AUTOSAR XML (schema 4-0-3)
standard types defined: Boolean, UInt16, UInt32, UInt8
package /AUTOSAR_Platform/DataConstrs
  range DC_Boolean: raw 0..1
  range DC_UInt16: raw 0..65535
  range DC_UInt8: raw 0..255
package /PATAC/MSM/ComponentTypes
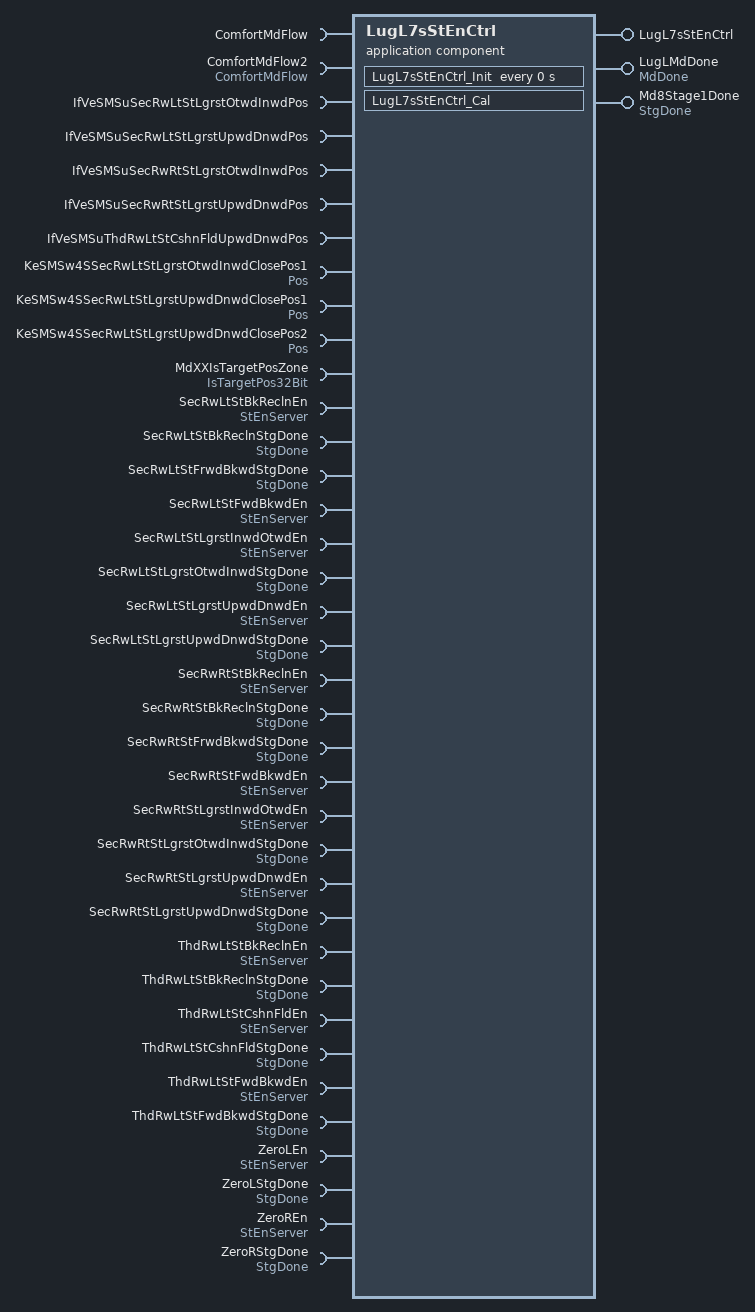
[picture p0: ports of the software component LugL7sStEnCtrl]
  application sw component type LugL7sStEnCtrl
    provide port LugL7sStEnCtrl: server-com-spec{operation=LugL7sStEnCtrl/Cal, queue-length=1}, provided-interface=LugL7sStEnCtrl
    provide port LugLMdDone: nonqueued-sender-com-spec{data-element=MdDone/Val, init-value=0}, provided-interface=MdDone
    provide port Md8Stage1Done: nonqueued-sender-com-spec{data-element=StgDone/Val, init-value=0}, provided-interface=StgDone
    37 x require port:
      ComfortMdFlow: client-com-spec=ComfortMdFlow/Cal, required-interface=ComfortMdFlow
      ComfortMdFlow2: client-com-spec=ComfortMdFlow/Cal, required-interface=ComfortMdFlow
      IfVeSMSuSecRwLtStLgrstOtwdInwdPos: nonqueued-receiver-com-spec{data-element=IfVeSMSuSecRwLtStLgrstOtwdInwdPos/Val, filter=data-filter-type=ALWAYS, init-value=0}, required-interface=IfVeSMSuSecRwLtStLgrstOtwdInwdPos
      IfVeSMSuSecRwLtStLgrstUpwdDnwdPos: nonqueued-receiver-com-spec{data-element=IfVeSMSuSecRwLtStLgrstUpwdDnwdPos/Val, filter=data-filter-type=ALWAYS, init-value=0}, required-interface=IfVeSMSuSecRwLtStLgrstUpwdDnwdPos
      IfVeSMSuSecRwRtStLgrstOtwdInwdPos: nonqueued-receiver-com-spec{data-element=IfVeSMSuSecRwRtStLgrstOtwdInwdPos/Val, filter=data-filter-type=ALWAYS, init-value=0}, required-interface=IfVeSMSuSecRwRtStLgrstOtwdInwdPos
      IfVeSMSuSecRwRtStLgrstUpwdDnwdPos: nonqueued-receiver-com-spec{data-element=IfVeSMSuSecRwRtStLgrstUpwdDnwdPos/Val, filter=data-filter-type=ALWAYS, init-value=0}, required-interface=IfVeSMSuSecRwRtStLgrstUpwdDnwdPos
      IfVeSMSuThdRwLtStCshnFldUpwdDnwdPos: nonqueued-receiver-com-spec{data-element=IfVeSMSuThdRwLtStCshnFldUpwdDnwdPos/Val, filter=data-filter-type=ALWAYS, init-value=0}, required-interface=IfVeSMSuThdRwLtStCshnFldUpwdDnwdPos
      KeSMSw4SSecRwLtStLgrstOtwdInwdClosePos1: parameter-require-com-spec{init-value=0, parameter=Val}, required-interface=Pos
      KeSMSw4SSecRwLtStLgrstUpwdDnwdClosePos1: parameter-require-com-spec{init-value=0, parameter=Val}, required-interface=Pos
      KeSMSw4SSecRwLtStLgrstUpwdDnwdClosePos2: parameter-require-com-spec{init-value=0, parameter=Val}, required-interface=Pos
      MdXXIsTargetPosZone: nonqueued-receiver-com-spec{data-element=IsTargetPos32Bit/Val, filter=data-filter-type=ALWAYS, init-value=0}, required-interface=IsTargetPos32Bit
      SecRwLtStBkReclnEn: required-com-specs=[Clear, Get, Set], required-interface=StEnServer
      SecRwLtStBkReclnStgDone: nonqueued-receiver-com-spec{data-element=StgDone/Val, filter=data-filter-type=ALWAYS, init-value=0}, required-interface=StgDone
      SecRwLtStFrwdBkwdStgDone: nonqueued-receiver-com-spec{data-element=StgDone/Val, filter=data-filter-type=ALWAYS, init-value=0}, required-interface=StgDone
      SecRwLtStFwdBkwdEn: required-com-specs=[Clear, Get, Set], required-interface=StEnServer
      SecRwLtStLgrstInwdOtwdEn: required-com-specs=[Clear, Get, Set], required-interface=StEnServer
      SecRwLtStLgrstOtwdInwdStgDone: nonqueued-receiver-com-spec{data-element=StgDone/Val, filter=data-filter-type=ALWAYS, init-value=0}, required-interface=StgDone
      SecRwLtStLgrstUpwdDnwdEn: required-com-specs=[Clear, Get, Set], required-interface=StEnServer
      SecRwLtStLgrstUpwdDnwdStgDone: nonqueued-receiver-com-spec{data-element=StgDone/Val, filter=data-filter-type=ALWAYS, init-value=0}, required-interface=StgDone
      SecRwRtStBkReclnEn: required-com-specs=[Clear, Get, Set], required-interface=StEnServer
      SecRwRtStBkReclnStgDone: nonqueued-receiver-com-spec{data-element=StgDone/Val, filter=data-filter-type=ALWAYS, init-value=0}, required-interface=StgDone
      SecRwRtStFrwdBkwdStgDone: nonqueued-receiver-com-spec{data-element=StgDone/Val, filter=data-filter-type=ALWAYS, init-value=0}, required-interface=StgDone
      SecRwRtStFwdBkwdEn: required-com-specs=[Clear, Get, Set], required-interface=StEnServer
      SecRwRtStLgrstInwdOtwdEn: required-com-specs=[Clear, Get, Set], required-interface=StEnServer
      SecRwRtStLgrstOtwdInwdStgDone: nonqueued-receiver-com-spec{data-element=StgDone/Val, filter=data-filter-type=ALWAYS, init-value=0}, required-interface=StgDone
      SecRwRtStLgrstUpwdDnwdEn: required-com-specs=[Clear, Get, Set], required-interface=StEnServer
      SecRwRtStLgrstUpwdDnwdStgDone: nonqueued-receiver-com-spec{data-element=StgDone/Val, filter=data-filter-type=ALWAYS, init-value=0}, required-interface=StgDone
      ThdRwLtStBkReclnEn: required-com-specs=[Clear, Get, Set], required-interface=StEnServer
      ThdRwLtStBkReclnStgDone: nonqueued-receiver-com-spec{data-element=StgDone/Val, filter=data-filter-type=ALWAYS, init-value=0}, required-interface=StgDone
      ThdRwLtStCshnFldEn: required-com-specs=[Clear, Get, Set], required-interface=StEnServer
      ThdRwLtStCshnFldStgDone: nonqueued-receiver-com-spec{data-element=StgDone/Val, filter=data-filter-type=ALWAYS, init-value=0}, required-interface=StgDone
      ThdRwLtStFwdBkwdEn: required-com-specs=[Clear, Get, Set], required-interface=StEnServer
      ThdRwLtStFwdBkwdStgDone: nonqueued-receiver-com-spec{data-element=StgDone/Val, filter=data-filter-type=ALWAYS, init-value=0}, required-interface=StgDone
      ZeroLEn: required-com-specs=[Clear, Get, Set], required-interface=StEnServer
      ZeroLStgDone: nonqueued-receiver-com-spec{data-element=StgDone/Val, filter=data-filter-type=ALWAYS, init-value=0}, required-interface=StgDone
      ZeroREn: required-com-specs=[Clear, Get, Set], required-interface=StEnServer
      ZeroRStgDone: nonqueued-receiver-com-spec{data-element=StgDone/Val, filter=data-filter-type=ALWAYS, init-value=0}, required-interface=StgDone
    behavior LugL7sStEnCtrl_InternalBehavior
      operation invoked event OIT_LugLStEnCtrl_Cal_LugL7sStEnCtrl_Cal: start-on-event=LugL7sStEnCtrl_Cal, operation=LugL7sStEnCtrl.Cal
      timing event LugL7sStEnCtrl_InitEvent: start-on-event=LugL7sStEnCtrl_Init, period=0
      runnable LugL7sStEnCtrl_Cal
        data-receive-point-by-arguments:
          19 x access:
            REC_IfVeSMSuSecRwLtStLgrstOtwdInwdPos_Val: accessed-variable=IfVeSMSuSecRwLtStLgrstOtwdInwdPos.Val
            REC_IfVeSMSuSecRwLtStLgrstUpwdDnwdPos_Val: accessed-variable=IfVeSMSuSecRwLtStLgrstUpwdDnwdPos.Val
            REC_IfVeSMSuSecRwRtStLgrstOtwdInwdPos_Val: accessed-variable=IfVeSMSuSecRwRtStLgrstOtwdInwdPos.Val
            REC_IfVeSMSuSecRwRtStLgrstUpwdDnwdPos_Val: accessed-variable=IfVeSMSuSecRwRtStLgrstUpwdDnwdPos.Val
            REC_IfVeSMSuThdRwLtStCshnFldUpwdDnwdPos_Val: accessed-variable=IfVeSMSuThdRwLtStCshnFldUpwdDnwdPos.Val
            REC_MdXXIsTargetPosZone_Val: accessed-variable=MdXXIsTargetPosZone.Val
            REC_SecRwLtStBkReclnStgDone_Val: accessed-variable=SecRwLtStBkReclnStgDone.Val
            REC_SecRwLtStFrwdBkwdStgDone_Val: accessed-variable=SecRwLtStFrwdBkwdStgDone.Val
            REC_SecRwLtStLgrstOtwdInwdStgDone_Val: accessed-variable=SecRwLtStLgrstOtwdInwdStgDone.Val
            REC_SecRwLtStLgrstUpwdDnwdStgDone_Val: accessed-variable=SecRwLtStLgrstUpwdDnwdStgDone.Val
            REC_SecRwRtStBkReclnStgDone_Val: accessed-variable=SecRwRtStBkReclnStgDone.Val
            REC_SecRwRtStFrwdBkwdStgDone_Val: accessed-variable=SecRwRtStFrwdBkwdStgDone.Val
            REC_SecRwRtStLgrstOtwdInwdStgDone_Val: accessed-variable=SecRwRtStLgrstOtwdInwdStgDone.Val
            REC_SecRwRtStLgrstUpwdDnwdStgDone_Val: accessed-variable=SecRwRtStLgrstUpwdDnwdStgDone.Val
            REC_ThdRwLtStBkReclnStgDone_Val: accessed-variable=ThdRwLtStBkReclnStgDone.Val
            REC_ThdRwLtStCshnFldStgDone_Val: accessed-variable=ThdRwLtStCshnFldStgDone.Val
            REC_ThdRwLtStFwdBkwdStgDone_Val: accessed-variable=ThdRwLtStFwdBkwdStgDone.Val
            REC_ZeroLStgDone_Val: accessed-variable=ZeroLStgDone.Val
            REC_ZeroRStgDone_Val: accessed-variable=ZeroRStgDone.Val
        data-send-points:
          access SEND_LugLMdDone_Val: accessed-variable=LugLMdDone.Val
          access SEND_Md8Stage1Done_Val: accessed-variable=Md8Stage1Done.Val
        parameter access PA_KeSMSw4SSecRwLtStLgrstOtwdInwdClosePos1_Val: accessed-parameter=KeSMSw4SSecRwLtStLgrstOtwdInwdClosePos1.Val
        parameter access PA_KeSMSw4SSecRwLtStLgrstUpwdDnwdClosePos1_Val: accessed-parameter=KeSMSw4SSecRwLtStLgrstUpwdDnwdClosePos1.Val
        parameter access PA_KeSMSw4SSecRwLtStLgrstUpwdDnwdClosePos2_Val: accessed-parameter=KeSMSw4SSecRwLtStLgrstUpwdDnwdClosePos2.Val
        28 x sync call, all with timeout=0:
          SC_ComfortMdFlow_Cal: operation=ComfortMdFlow.Cal
          SC_ComfortMdFlow2_Cal: operation=ComfortMdFlow2.Cal
          SC_SecRwLtStBkReclnEn_Clear: operation=SecRwLtStBkReclnEn.Clear
          SC_SecRwLtStBkReclnEn_Set: operation=SecRwLtStBkReclnEn.Set
          SC_SecRwLtStFwdBkwdEn_Clear: operation=SecRwLtStFwdBkwdEn.Clear
          SC_SecRwLtStFwdBkwdEn_Set: operation=SecRwLtStFwdBkwdEn.Set
          SC_SecRwLtStLgrstInwdOtwdEn_Clear: operation=SecRwLtStLgrstInwdOtwdEn.Clear
          SC_SecRwLtStLgrstInwdOtwdEn_Set: operation=SecRwLtStLgrstInwdOtwdEn.Set
          SC_SecRwLtStLgrstUpwdDnwdEn_Clear: operation=SecRwLtStLgrstUpwdDnwdEn.Clear
          SC_SecRwLtStLgrstUpwdDnwdEn_Set: operation=SecRwLtStLgrstUpwdDnwdEn.Set
          SC_SecRwRtStBkReclnEn_Clear: operation=SecRwRtStBkReclnEn.Clear
          SC_SecRwRtStBkReclnEn_Set: operation=SecRwRtStBkReclnEn.Set
          SC_SecRwRtStFwdBkwdEn_Clear: operation=SecRwRtStFwdBkwdEn.Clear
          SC_SecRwRtStFwdBkwdEn_Set: operation=SecRwRtStFwdBkwdEn.Set
          SC_SecRwRtStLgrstInwdOtwdEn_Clear: operation=SecRwRtStLgrstInwdOtwdEn.Clear
          SC_SecRwRtStLgrstInwdOtwdEn_Set: operation=SecRwRtStLgrstInwdOtwdEn.Set
          SC_SecRwRtStLgrstUpwdDnwdEn_Clear: operation=SecRwRtStLgrstUpwdDnwdEn.Clear
          SC_SecRwRtStLgrstUpwdDnwdEn_Set: operation=SecRwRtStLgrstUpwdDnwdEn.Set
          SC_ThdRwLtStBkReclnEn_Clear: operation=ThdRwLtStBkReclnEn.Clear
          SC_ThdRwLtStBkReclnEn_Set: operation=ThdRwLtStBkReclnEn.Set
          SC_ThdRwLtStCshnFldEn_Clear: operation=ThdRwLtStCshnFldEn.Clear
          SC_ThdRwLtStCshnFldEn_Set: operation=ThdRwLtStCshnFldEn.Set
          SC_ThdRwLtStFwdBkwdEn_Clear: operation=ThdRwLtStFwdBkwdEn.Clear
          SC_ThdRwLtStFwdBkwdEn_Set: operation=ThdRwLtStFwdBkwdEn.Set
          SC_ZeroLEn_Clear: operation=ZeroLEn.Clear
          SC_ZeroLEn_Set: operation=ZeroLEn.Set
          SC_ZeroREn_Clear: operation=ZeroREn.Clear
          SC_ZeroREn_Set: operation=ZeroREn.Set
      runnable LugL7sStEnCtrl_Init
        parameter access PA_KeSMSw4SSecRwLtStLgrstOtwdInwdClosePos1_Val: accessed-parameter=KeSMSw4SSecRwLtStLgrstOtwdInwdClosePos1.Val
        parameter access PA_KeSMSw4SSecRwLtStLgrstUpwdDnwdClosePos1_Val: accessed-parameter=KeSMSw4SSecRwLtStLgrstUpwdDnwdClosePos1.Val
        parameter access PA_KeSMSw4SSecRwLtStLgrstUpwdDnwdClosePos2_Val: accessed-parameter=KeSMSw4SSecRwLtStLgrstUpwdDnwdClosePos2.Val
  swc implementation LugL7sStEnCtrl_Implementation: behavior=LugL7sStEnCtrl_InternalBehavior
    code-descriptors:
      code Default: artifact-descriptors=autosar-engineering-object={short-label=Default, category=SWSRC}
package /PATAC/MSM/ModeAdjust/CalPortInterface
  parameter interface Pos
    parameter data prototype Val: sw-calibration-access=READ-WRITE, type=UInt16
package /PATAC/MSM/ModeAdjust/Interfaces
  sender receiver interface IfVeSMSuThdRwLtStCshnFldUpwdDnwdPos: invalidation-policy{data-element=IfVeSMSuThdRwLtStCshnFldUpwdDnwdPos/Val, handle-invalid=DONT-INVALIDATE}
    data Val: type=UInt16
package /PATAC/MSM/ModeAdjust/PortInterface
  client server interface ComfortMdFlow
    operation Cal
      14 x arg, all with server-argument-impl-policy=USE-ARGUMENT-TYPE:
        LgrstUpwdDnwdPos: type=UInt16, direction=IN
        LgrstUpwdDnwdClosePos1: type=UInt16, direction=IN
        LgrstUpwdStgDone: type=Implementation/Boolean, direction=IN
        ZeroStgDone: type=Implementation/Boolean, direction=IN
        LgrstInwdStgDone: type=Implementation/Boolean, direction=IN
        Failflg: type=Implementation/Boolean, direction=OUT
        LgrstInwdOtwdEn: type=Implementation/Boolean, direction=OUT
        LgrstUpwdDnwdEn: type=Implementation/Boolean, direction=OUT
        ZeroEn: type=Implementation/Boolean, direction=OUT
        BkReclnStgDone: type=DataTypes/Boolean, direction=IN
        BkReclnEn: type=DataTypes/Boolean, direction=OUT
        LgrstUpwdDnwdClosePos2: type=UInt16, direction=IN
        LgrstInwdOtwdClosePos1: type=UInt16, direction=IN
        LgrstInwdOtwdPos: type=UInt16, direction=IN
  client server interface LugL7sStEnCtrl
    operation Cal
  client server interface StEnServer
    operation Clear
      arg data: type=UInt8, direction=IN, server-argument-impl-policy=USE-ARGUMENT-TYPE
    operation Get
      arg data: type=UInt32, direction=OUT, server-argument-impl-policy=USE-ARGUMENT-TYPE
    operation Set
      arg data: type=UInt8, direction=IN, server-argument-impl-policy=USE-ARGUMENT-TYPE
  sender receiver interface IsTargetPos32Bit: invalidation-policy{data-element=IsTargetPos32Bit/Val, handle-invalid=DONT-INVALIDATE}
    data Val: type=UInt32
  sender receiver interface MdDone: invalidation-policy{data-element=MdDone/Val, handle-invalid=DONT-INVALIDATE}
    data Val: type=UInt8
  sender receiver interface StgDone: invalidation-policy{data-element=StgDone/Val, handle-invalid=DONT-INVALIDATE}
    data Val: type=Implementation/Boolean
package /PATAC/MSM/PortInterfaces
  4 x sender receiver interface:
    IfVeSMSuSecRwLtStLgrstOtwdInwdPos: invalidation-policy{data-element=IfVeSMSuSecRwLtStLgrstOtwdInwdPos/Val, handle-invalid=DONT-INVALIDATE}
      data Val: type=UInt16
    IfVeSMSuSecRwLtStLgrstUpwdDnwdPos: invalidation-policy{data-element=IfVeSMSuSecRwLtStLgrstUpwdDnwdPos/Val, handle-invalid=DONT-INVALIDATE}
      data Val: type=UInt16
    IfVeSMSuSecRwRtStLgrstOtwdInwdPos: invalidation-policy{data-element=IfVeSMSuSecRwRtStLgrstOtwdInwdPos/Val, handle-invalid=DONT-INVALIDATE}
      data Val: type=UInt16
    IfVeSMSuSecRwRtStLgrstUpwdDnwdPos: invalidation-policy{data-element=IfVeSMSuSecRwRtStLgrstUpwdDnwdPos/Val, handle-invalid=DONT-INVALIDATE}
      data Val: type=UInt16
